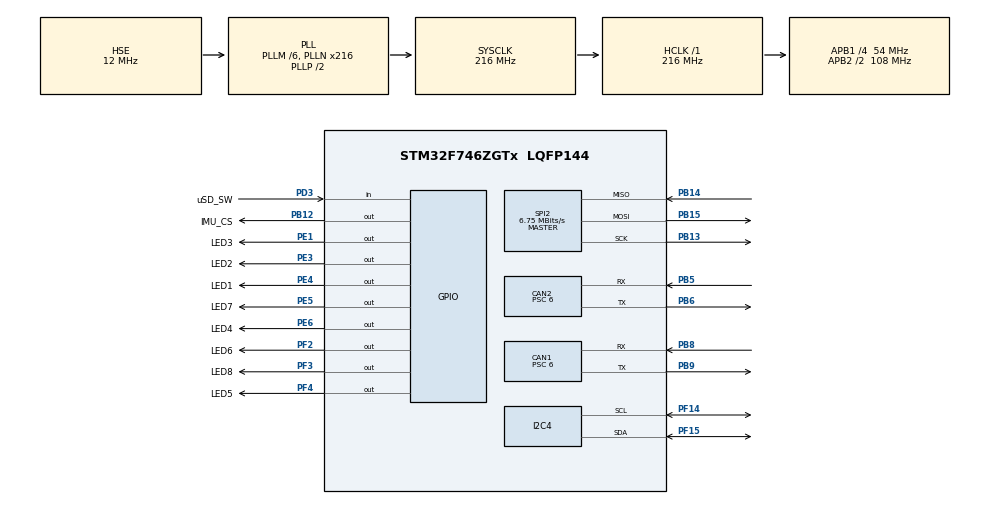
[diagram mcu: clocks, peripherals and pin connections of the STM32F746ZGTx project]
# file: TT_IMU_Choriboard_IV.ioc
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CAN1.BS1=CAN_BS1_6TQ
CAN1.BS2=CAN_BS2_2TQ
CAN1.CalculateBaudRate=1000000
CAN1.CalculateTimeBit=1000
CAN1.CalculateTimeQuantum=111.11111111111111
CAN1.NART=DISABLE
CAN1.Prescaler=6
CAN1.SJW=CAN_SJW_2TQ
CAN2.BS1=CAN_BS1_6TQ
CAN2.BS2=CAN_BS2_2TQ
CAN2.CalculateBaudRate=1000000
CAN2.CalculateTimeBit=1000
CAN2.CalculateTimeQuantum=111.11111111111111
CAN2.Prescaler=6
CAN2.SJW=CAN_SJW_2TQ
I2C4.Timing=0x20404768
IWDG.Reload=11
Mcu.Family=STM32F7
Mcu.Name=STM32F746ZGTx
Mcu.Package=LQFP144
NVIC.CAN1_RX0_IRQn=true\:0\:0\:false\:false\:true\:true\:true\:true
NVIC.PriorityGroup=NVIC_PRIORITYGROUP_4
NVIC.TIM5_IRQn=true\:0\:0\:false\:false\:true\:true\:true\:true
PA13.Mode=Serial_Wire
PA13.Signal=SYS_JTMS-SWDIO
PA14.Mode=Serial_Wire
PA14.Signal=SYS_JTCK-SWCLK
PB12.GPIO_Label=IMU_CS
PB12.PinState=GPIO_PIN_SET
PB12.Signal=GPIO_Output
PB13.Mode=Full_Duplex_Master
PB13.Signal=SPI2_SCK
PB14.Mode=Full_Duplex_Master
PB14.Signal=SPI2_MISO
PB15.Mode=Full_Duplex_Master
PB15.Signal=SPI2_MOSI
PB5.Mode=CAN_Activate
PB5.Signal=CAN2_RX
PB6.Mode=CAN_Activate
PB6.Signal=CAN2_TX
PB8.Mode=CAN_Activate
PB8.Signal=CAN1_RX
PB9.Mode=CAN_Activate
PB9.Signal=CAN1_TX
PD3.GPIO_Label=uSD_SW
PD3.Signal=GPIO_Input
PE1.GPIO_Label=LED3
PE1.Signal=GPIO_Output
PE3.GPIO_Label=LED2
PE3.Signal=GPIO_Output
PE4.GPIO_Label=LED1
PE4.Signal=GPIO_Output
PE5.GPIO_Label=LED7
PE5.Signal=GPIO_Output
PE6.GPIO_Label=LED4
PE6.Signal=GPIO_Output
PF14.Mode=I2C
PF14.Signal=I2C4_SCL
PF15.Mode=I2C
PF15.Signal=I2C4_SDA
PF2.GPIO_Label=LED6
PF2.Signal=GPIO_Output
PF3.GPIO_Label=LED8
PF3.Signal=GPIO_Output
PF4.GPIO_Label=LED5
PF4.Signal=GPIO_Output
PH0/OSC_IN.Mode=HSE-External-Oscillator
PH0/OSC_IN.Signal=RCC_OSC_IN
PH1/OSC_OUT.Mode=HSE-External-Oscillator
PH1/OSC_OUT.Signal=RCC_OSC_OUT
ProjectManager.HeapSize=0x200
ProjectManager.StackSize=0x400
ProjectManager.TargetToolchain=STM32CubeIDE
RCC.AHBFreq_Value=216000000
RCC.APB1CLKDivider=RCC_HCLK_DIV4
RCC.APB1Freq_Value=54000000
RCC.APB1TimFreq_Value=108000000
RCC.APB2CLKDivider=RCC_HCLK_DIV2
RCC.APB2Freq_Value=108000000
RCC.APB2TimFreq_Value=216000000
RCC.CortexFreq_Value=216000000
RCC.HCLKFreq_Value=216000000
RCC.HSE_VALUE=12000000
RCC.HSI_VALUE=16000000
RCC.LSE_VALUE=32768
RCC.PLLM=6
RCC.PLLN=216
RCC.PLLQ=9
RCC.PLLSourceVirtual=RCC_PLLSOURCE_HSE
RCC.SDMMCClockSelection=RCC_SDMMC1CLKSOURCE_CLK48
RCC.SYSCLKFreq_VALUE=216000000
RCC.SYSCLKSource=RCC_SYSCLKSOURCE_PLLCLK
RCC.USBFreq_Value=48000000
RCC.VCOOutputFreq_Value=432000000
SPI2.BaudRatePrescaler=SPI_BAUDRATEPRESCALER_8
SPI2.CLKPhase=SPI_PHASE_2EDGE
SPI2.CalculateBaudRate=6.75 MBits/s
SPI2.DataSize=SPI_DATASIZE_8BIT
SPI2.Direction=SPI_DIRECTION_2LINES
SPI2.Mode=SPI_MODE_MASTER
SPI2.VirtualType=VM_MASTER
TIM5.AutoReloadPreload=TIM_AUTORELOAD_PRELOAD_DISABLE
TIM5.Period=1000-1
TIM5.Prescaler=108-1
VP_IWDG_VS_IWDG.Mode=IWDG_Activate
VP_TIM5_VS_ClockSourceINT.Mode=Internal
board=custom

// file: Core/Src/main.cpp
/* USER CODE BEGIN Header */
/**
  ******************************************************************************
  * @file           : main.c
  * @brief          : Main program body
  ******************************************************************************
  * @attention
  *
  * Copyright (c) 2024 STMicroelectronics.
  * All rights reserved.
  *
  * This software is licensed under terms that can be found in the LICENSE file
  * in the root directory of this software component.
  * If no LICENSE file comes with this software, it is provided AS-IS.
  *
  ******************************************************************************
  */
/* USER CODE END Header */
#include "main.h"
#include "can.h"
#include "i2c.h"
#include "spi.h"
#include "tim.h"
#include "gpio.h"

/* USER CODE BEGIN Includes */
#include "system.h"
/* USER CODE END Includes */

void SystemClock_Config(void);

int main(void)
{

  /* MCU Configuration--------------------------------------------------------*/

  /* Reset of all peripherals, Initializes the Flash interface and the Systick. */
  HAL_Init();

  /* Configure the system clock */
  SystemClock_Config();

  /* Initialize all configured peripherals */
  MX_GPIO_Init();
  MX_SPI2_Init();
  MX_I2C4_Init();
  MX_CAN1_Init();
  MX_CAN2_Init();
  MX_TIM5_Init();
  /* USER CODE BEGIN 2 */

  //HAL_Delay(2000);

  system_init();

  /* USER CODE END 2 */

  /* Infinite loop */
  while (1)
  {

    /* USER CODE BEGIN 3 */
	  system_run_active_mode();
  }
  /* USER CODE END 3 */
}

void SystemClock_Config(void)
{
  RCC_OscInitTypeDef RCC_OscInitStruct = {0};
  RCC_ClkInitTypeDef RCC_ClkInitStruct = {0};

  /** Configure the main internal regulator output voltage
  */
  __HAL_RCC_PWR_CLK_ENABLE();
  __HAL_PWR_VOLTAGESCALING_CONFIG(PWR_REGULATOR_VOLTAGE_SCALE1);

  /** Initializes the RCC Oscillators according to the specified parameters
  * in the RCC_OscInitTypeDef structure.
  */
  RCC_OscInitStruct.OscillatorType = RCC_OSCILLATORTYPE_LSI|RCC_OSCILLATORTYPE_HSE;
  RCC_OscInitStruct.HSEState = RCC_HSE_ON;
  RCC_OscInitStruct.LSIState = RCC_LSI_ON;
  RCC_OscInitStruct.PLL.PLLState = RCC_PLL_ON;
  RCC_OscInitStruct.PLL.PLLSource = RCC_PLLSOURCE_HSE;
  RCC_OscInitStruct.PLL.PLLM = 6;
  RCC_OscInitStruct.PLL.PLLN = 216;
  RCC_OscInitStruct.PLL.PLLP = RCC_PLLP_DIV2;
  RCC_OscInitStruct.PLL.PLLQ = 9;
  if (HAL_RCC_OscConfig(&RCC_OscInitStruct) != HAL_OK)
  {
    Error_Handler();
  }

  /** Activate the Over-Drive mode
  */
  if (HAL_PWREx_EnableOverDrive() != HAL_OK)
  {
    Error_Handler();
  }

  /** Initializes the CPU, AHB and APB buses clocks
  */
  RCC_ClkInitStruct.ClockType = RCC_CLOCKTYPE_HCLK|RCC_CLOCKTYPE_SYSCLK
                              |RCC_CLOCKTYPE_PCLK1|RCC_CLOCKTYPE_PCLK2;
  RCC_ClkInitStruct.SYSCLKSource = RCC_SYSCLKSOURCE_PLLCLK;
  RCC_ClkInitStruct.AHBCLKDivider = RCC_SYSCLK_DIV1;
  RCC_ClkInitStruct.APB1CLKDivider = RCC_HCLK_DIV4;
  RCC_ClkInitStruct.APB2CLKDivider = RCC_HCLK_DIV2;

  if (HAL_RCC_ClockConfig(&RCC_ClkInitStruct, FLASH_LATENCY_7) != HAL_OK)
  {
    Error_Handler();
  }
}

void Error_Handler(void)
{
  __disable_irq();
  while (1)
  {
  }
}
